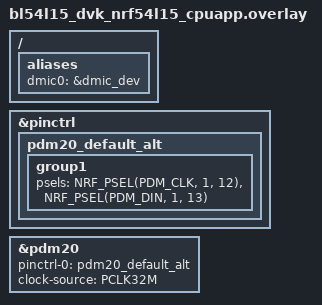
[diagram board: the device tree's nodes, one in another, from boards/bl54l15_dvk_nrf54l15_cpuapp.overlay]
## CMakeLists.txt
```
# SPDX-License-Identifier: Apache-2.0

cmake_minimum_required(VERSION 3.28.0)

find_package(Zephyr REQUIRED HINTS $ENV{ZEPHYR_BASE})
project(dmic)

target_sources(app PRIVATE src/main.c)
```

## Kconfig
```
# Copyright 2025 NXP
# SPDX-License-Identifier: Apache-2.0

source "Kconfig.zephyr"

config SAMPLE_BIT_WIDTH
	int "Sample bit width"
	default 32 if DT_HAS_NXP_MICFIL_ENABLED
	default 16
	help
	  PCM sample bit width.

config SAMPLE_HW_CHANNEL_INDEX
	int "hardware controller index"
	default 0
	help
	  Specifies the index of the hardware controller.
```

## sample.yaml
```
sample:
  name: DMIC sample
tests:
  sample.drivers.audio.dmic:
    tags: dmic
    filter: dt_nodelabel_enabled("dmic_dev")
    extra_args:
      - platform:arduino_giga_r1/stm32h747xx/m7:SHIELD=arduino_giga_display_shield
    integration_platforms:
      - nrf52840dk/nrf52840
      - nrf5340dk/nrf5340/cpuapp
      - nrf54l15dk/nrf54l15/cpuapp
      - apollo510_evb
      - stm32f769i_disco
      - arduino_giga_r1/stm32h747xx/m7
    harness: console
    harness_config:
      type: multi_line
      ordered: true
      regex:
        - "DMIC sample"
        - "Exiting"
```

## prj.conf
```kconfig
CONFIG_AUDIO=y
CONFIG_AUDIO_DMIC=y

CONFIG_LOG=y
```

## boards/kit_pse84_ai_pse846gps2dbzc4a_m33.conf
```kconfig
# SPDX-FileCopyrightText: <text>Copyright (c) 2026 Infineon Technologies AG,
# or an affiliate of Infineon Technologies AG. All rights reserved.</text>
#
# SPDX-License-Identifier: Apache-2.0

CONFIG_SAMPLE_HW_CHANNEL_INDEX=1
```

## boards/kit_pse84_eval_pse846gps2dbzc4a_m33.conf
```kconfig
# SPDX-FileCopyrightText: Copyright (c) 2026 Infineon Technologies AG,
# SPDX-FileCopyrightText: or an affiliate of Infineon Technologies AG. All rights reserved.
#
# SPDX-License-Identifier: Apache-2.0

CONFIG_SAMPLE_HW_CHANNEL_INDEX=1
```

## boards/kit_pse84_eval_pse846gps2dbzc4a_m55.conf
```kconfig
# Copyright (c) 2026 Infineon Technologies AG,
# or an affiliate of Infineon Technologies AG.
#
# SPDX-License-Identifier: Apache-2.0

CONFIG_HW_CHANNEL_INDEX=1
CONFIG_MAIN_STACK_SIZE=4096
```

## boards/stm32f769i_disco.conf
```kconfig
# SPDX-FileCopyrightText: Copyright (c) 2026 STMicroelectronics
# SPDX-License-Identifier: Apache-2.0

# PDM filter index (pdm0); DFSDM channel comes from devicetree channel@N reg
CONFIG_SAMPLE_HW_CHANNEL_INDEX=0
```

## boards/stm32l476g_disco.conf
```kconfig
# SPDX-FileCopyrightText: Copyright (c) 2026 STMicroelectronics
# SPDX-License-Identifier: Apache-2.0

CONFIG_SAMPLE_HW_CHANNEL_INDEX=2
```

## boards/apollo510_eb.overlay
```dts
/*
 * Copyright (c) 2025 Ambiq Micro Inc.
 *
 * SPDX-License-Identifier: Apache-2.0
 */

dmic_dev: &pdm0 {
	status = "okay";
};
```

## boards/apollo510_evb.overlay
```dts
/ {
	aliases {
		dmic0 = &dmic_dev;
	};
};

dmic_dev: &pdm0 {
	pdm-buffer-location = "SRAM_NO_CACHE";
	pdm-buffer-size = <640>;
	status = "okay";
};
```

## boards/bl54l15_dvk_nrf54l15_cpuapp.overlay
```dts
/*
 * Copyright (c) 2024 Nordic Semiconductor ASA
 * Copyright (c) 2025 Ezurio LLC
 *
 * SPDX-License-Identifier: Apache-2.0
 */

/ {
	aliases {
		dmic0 = &dmic_dev;
	};
};

&pinctrl {
	pdm20_default_alt: pdm20_default_alt {
		group1 {
			psels = <NRF_PSEL(PDM_CLK, 1, 12)>,
				<NRF_PSEL(PDM_DIN, 1, 13)>;
		};
	};
};

dmic_dev: &pdm20 {
	pinctrl-0 = <&pdm20_default_alt>;
	pinctrl-names = "default";
	clock-source = "PCLK32M";
	status = "okay";
};
```

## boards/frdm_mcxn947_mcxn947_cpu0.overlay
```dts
/*
 * SPDX-License-Identifier: Apache-2.0
 *
 * Copyright 2025 NXP
 */

/ {
	aliases {
		dmic0 = &dmic_dev;
	};
};

dmic_dev: &micfil {
	status = "okay";

	channel0: micfil-channel@0 {
		status = "okay";
	};

	channel1: micfil-channel@1 {
		status = "okay";
	};
};
```

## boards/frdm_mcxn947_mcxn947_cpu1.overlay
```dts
/*
 * SPDX-License-Identifier: Apache-2.0
 *
 * Copyright 2025 NXP
 */

dmic_dev: &micfil {
	status = "okay";

	channel0: micfil-channel@0 {
		status = "okay";
	};

	channel1: micfil-channel@1 {
		status = "okay";
	};
};
```

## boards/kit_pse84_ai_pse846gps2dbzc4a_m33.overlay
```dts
/*
 * SPDX-FileCopyrightText: <text>Copyright (c) 2026 Infineon Technologies AG,
 * or an affiliate of Infineon Technologies AG.</text>
 *
 * SPDX-License-Identifier: Apache-2.0
 */

#include "kit_pse84_common.overlay"
```

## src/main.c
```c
/*
 * Copyright (c) 2021 Nordic Semiconductor ASA
 *
 * SPDX-License-Identifier: Apache-2.0
 */

#include <zephyr/kernel.h>
#include <zephyr/audio/dmic.h>

#include <zephyr/logging/log.h>
LOG_MODULE_REGISTER(dmic_sample);

#define MAX_SAMPLE_RATE  16000
#define SAMPLE_BIT_WIDTH CONFIG_SAMPLE_BIT_WIDTH
#define PDM_CTL_IDX      CONFIG_SAMPLE_HW_CHANNEL_INDEX
#define BYTES_PER_SAMPLE SAMPLE_BIT_WIDTH / 8
/* Milliseconds to wait for a block to be read. */
#define READ_TIMEOUT     1000

/* Size of a block for 100 ms of audio data. */
#define BLOCK_SIZE(_sample_rate, _number_of_channels) \
	(BYTES_PER_SAMPLE * (_sample_rate / 10) * _number_of_channels)

/* Driver will allocate blocks from this slab to receive audio data into them.
 * Application, after getting a given block from the driver and processing its
 * data, needs to free that block.
 */
#define MAX_BLOCK_SIZE   BLOCK_SIZE(MAX_SAMPLE_RATE, 2)
#define BLOCK_COUNT      4

/* Cache-line align the blocks so cache maintenance on one block cannot
 * corrupt a neighbouring block
 */
#ifdef CONFIG_DCACHE_LINE_SIZE
#define SLAB_ALIGN MAX(4, CONFIG_DCACHE_LINE_SIZE)
#else
#define SLAB_ALIGN 4
#endif

K_MEM_SLAB_DEFINE_STATIC(mem_slab, MAX_BLOCK_SIZE, BLOCK_COUNT, SLAB_ALIGN);

static uint8_t capture_storage[BLOCK_COUNT * MAX_BLOCK_SIZE * 2];

static int do_pdm_transfer(const struct device *dmic_dev,
			   struct dmic_cfg *cfg,
			   size_t block_count)
{
	int ret;

	LOG_INF("PCM output rate: %u, channels: %u",
		cfg->streams[0].pcm_rate, cfg->channel.req_num_chan);

	ret = dmic_configure(dmic_dev, cfg);
	if (ret < 0) {
		LOG_ERR("Failed to configure the driver: %d", ret);
		return ret;
	}

	ret = dmic_trigger(dmic_dev, DMIC_TRIGGER_START);
	if (ret < 0) {
		LOG_ERR("START trigger failed: %d", ret);
		return ret;
	}

	for (int i = 0; i < block_count; ++i) {
		void *buffer;
		size_t size;

		ret = dmic_read(dmic_dev, 0, &buffer, &size, READ_TIMEOUT);
		if (ret < 0) {
			LOG_ERR("%d - read failed: %d", i, ret);
			return ret;
		}

		LOG_INF("%d - got buffer %p of %u bytes", i, buffer, size);

		if (size <= sizeof(capture_storage)) {
			memcpy(capture_storage + i * size, buffer, size);
		} else {
			LOG_WRN_ONCE("capture_storage overflow");
		}
		k_mem_slab_free(&mem_slab, buffer);
	}

	ret = dmic_trigger(dmic_dev, DMIC_TRIGGER_STOP);
	if (ret < 0) {
		LOG_ERR("STOP trigger failed: %d", ret);
		return ret;
	}

	return ret;
}

int main(void)
{
	const struct device *const dmic_dev = DEVICE_DT_GET(DT_ALIAS(dmic0));
	int ret;

	LOG_INF("DMIC sample");

	if (!device_is_ready(dmic_dev)) {
		LOG_ERR("%s is not ready", dmic_dev->name);
		return 0;
	}

	struct pcm_stream_cfg stream = {
		.pcm_width = SAMPLE_BIT_WIDTH,
		.mem_slab  = &mem_slab,
	};
	struct dmic_cfg cfg = {
		.io = {
			/* These fields can be used to limit the PDM clock
			 * configurations that the driver is allowed to use
			 * to those supported by the microphone.
			 */
			.min_pdm_clk_freq = 1000000,
			.max_pdm_clk_freq = 3500000,
			.min_pdm_clk_dc   = 40,
			.max_pdm_clk_dc   = 60,
		},
		.streams = &stream,
		.channel = {
			.req_num_streams = 1,
		},
	};

	cfg.channel.req_num_chan = 1;
	cfg.channel.req_chan_map_lo =
		dmic_build_channel_map(0, PDM_CTL_IDX, PDM_CHAN_LEFT);
	cfg.streams[0].pcm_rate = MAX_SAMPLE_RATE;
	cfg.streams[0].block_size =
		BLOCK_SIZE(cfg.streams[0].pcm_rate, cfg.channel.req_num_chan);

	ret = do_pdm_transfer(dmic_dev, &cfg, 2 * BLOCK_COUNT);
	if (ret < 0) {
		return 0;
	}

	cfg.channel.req_num_chan = 2;
	cfg.channel.req_chan_map_lo =
		dmic_build_channel_map(0, PDM_CTL_IDX, PDM_CHAN_LEFT) |
		dmic_build_channel_map(1, PDM_CTL_IDX, PDM_CHAN_RIGHT);
	cfg.streams[0].pcm_rate = MAX_SAMPLE_RATE;
	cfg.streams[0].block_size =
		BLOCK_SIZE(cfg.streams[0].pcm_rate, cfg.channel.req_num_chan);

	ret = do_pdm_transfer(dmic_dev, &cfg, 2 * BLOCK_COUNT);
	if (ret < 0) {
		return 0;
	}

	LOG_INF("Exiting");
	return 0;
}
```
